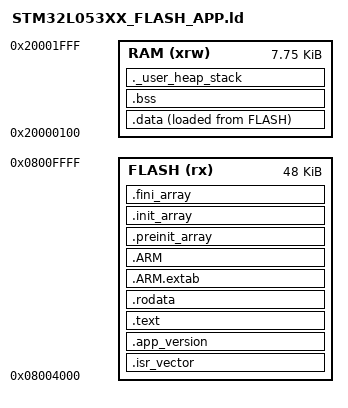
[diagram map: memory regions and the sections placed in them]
/* Linker script for STM32L053R8 application (with bootloader)
 * Flash: 48K starting at 0x08004000 (after 16K bootloader + metadata)
 * RAM:   first 0x100 bytes reserved for vector table copy (M0+ has no VTOR),
 *        remaining 7.75K available for data/bss/heap/stack.
 *        _estack still points to true end of RAM (0x20002000).
 */

ENTRY(Reset_Handler)

_estack = 0x20002000;
_Min_Heap_Size = 0x200;
_Min_Stack_Size = 0x400;

MEMORY
{
  RAM   (xrw) : ORIGIN = 0x20000100, LENGTH = 8K - 0x100
  FLASH (rx)  : ORIGIN = 0x08004000, LENGTH = 48K
}

SECTIONS
{
  .isr_vector :
  {
    . = ALIGN(4);
    KEEP(*(.isr_vector))
    . = ALIGN(4);
  } >FLASH

  /* App version stamp -- placed immediately after the vector table at a
   * well-known offset so the host updater can extract the build number
   * from the .bin file before flashing. Convention documented in
   * PROTOCOL.md ("App version stamp"). */
  .app_version :
  {
    . = ALIGN(4);
    KEEP(*(.app_version))
    . = ALIGN(4);
  } >FLASH

  .text :
  {
    . = ALIGN(4);
    *(.text)
    *(.text*)
    *(.glue_7)
    *(.glue_7t)
    *(.eh_frame)

    KEEP (*(.init))
    KEEP (*(.fini))

    . = ALIGN(4);
    _etext = .;
  } >FLASH

  .rodata :
  {
    . = ALIGN(4);
    *(.rodata)
    *(.rodata*)
    . = ALIGN(4);
  } >FLASH

  .ARM.extab (READONLY) :
  {
    . = ALIGN(4);
    *(.ARM.extab* .gnu.linkonce.armextab.*)
    . = ALIGN(4);
  } >FLASH

  .ARM (READONLY) :
  {
    . = ALIGN(4);
    __exidx_start = .;
    *(.ARM.exidx*)
    __exidx_end = .;
    . = ALIGN(4);
  } >FLASH

  .preinit_array (READONLY) :
  {
    . = ALIGN(4);
    PROVIDE_HIDDEN (__preinit_array_start = .);
    KEEP (*(.preinit_array*))
    PROVIDE_HIDDEN (__preinit_array_end = .);
    . = ALIGN(4);
  } >FLASH

  .init_array (READONLY) :
  {
    . = ALIGN(4);
    PROVIDE_HIDDEN (__init_array_start = .);
    KEEP (*(SORT(.init_array.*)))
    KEEP (*(.init_array*))
    PROVIDE_HIDDEN (__init_array_end = .);
    . = ALIGN(4);
  } >FLASH

  .fini_array (READONLY) :
  {
    . = ALIGN(4);
    PROVIDE_HIDDEN (__fini_array_start = .);
    KEEP (*(SORT(.fini_array.*)))
    KEEP (*(.fini_array*))
    PROVIDE_HIDDEN (__fini_array_end = .);
    . = ALIGN(4);
  } >FLASH

  _sidata = LOADADDR(.data);

  .data :
  {
    . = ALIGN(4);
    _sdata = .;
    *(.data)
    *(.data*)
    *(.RamFunc)
    *(.RamFunc*)

    . = ALIGN(4);
    _edata = .;
  } >RAM AT> FLASH

  . = ALIGN(4);
  .bss :
  {
    _sbss = .;
    __bss_start__ = _sbss;
    *(.bss)
    *(.bss*)
    *(COMMON)

    . = ALIGN(4);
    _ebss = .;
    __bss_end__ = _ebss;
  } >RAM

  ._user_heap_stack :
  {
    . = ALIGN(8);
    PROVIDE ( end = . );
    PROVIDE ( _end = . );
    . = . + _Min_Heap_Size;
    . = . + _Min_Stack_Size;
    . = ALIGN(8);
  } >RAM

  /DISCARD/ :
  {
    libc.a ( * )
    libm.a ( * )
    libgcc.a ( * )
  }
}
